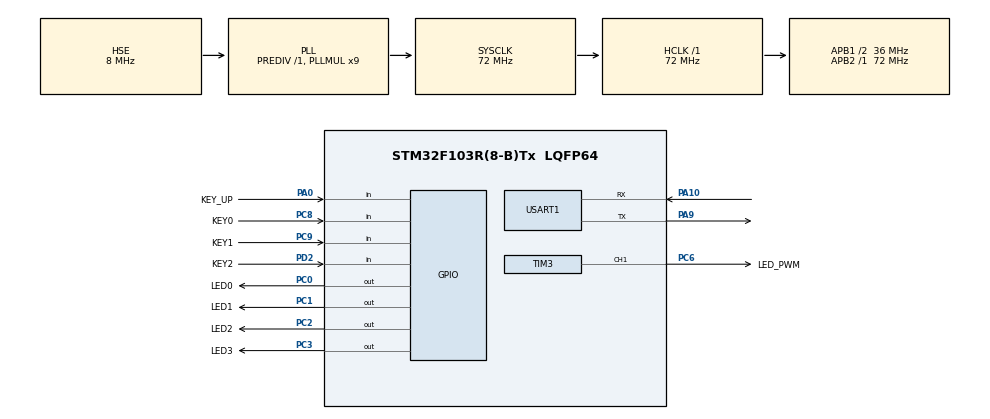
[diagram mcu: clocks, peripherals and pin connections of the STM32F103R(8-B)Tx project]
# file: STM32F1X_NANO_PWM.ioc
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Mcu.Family=STM32F1
Mcu.Name=STM32F103R(8-B)Tx
Mcu.Package=LQFP64
NVIC.PriorityGroup=NVIC_PRIORITYGROUP_2
NVIC.TIM3_IRQn=true\:1\:0\:true\:false\:true\:true\:true\:true
PA0-WKUP.GPIO_Label=KEY_UP
PA0-WKUP.GPIO_PuPd=GPIO_PULLDOWN
PA0-WKUP.Signal=GPIO_Input
PA10.Mode=Asynchronous
PA10.Signal=USART1_RX
PA9.Mode=Asynchronous
PA9.Signal=USART1_TX
PC0.GPIO_Label=LED0
PC0.Signal=GPIO_Output
PC1.GPIO_Label=LED1
PC1.Signal=GPIO_Output
PC14-OSC32_IN.Mode=LSE-External-Oscillator
PC14-OSC32_IN.Signal=RCC_OSC32_IN
PC15-OSC32_OUT.Mode=LSE-External-Oscillator
PC15-OSC32_OUT.Signal=RCC_OSC32_OUT
PC2.GPIO_Label=LED2
PC2.Signal=GPIO_Output
PC3.GPIO_Label=LED3
PC3.Signal=GPIO_Output
PC6.GPIO_Label=LED_PWM
PC6.Signal=S_TIM3_CH1
PC8.GPIO_Label=KEY0
PC8.GPIO_PuPd=GPIO_PULLUP
PC8.Signal=GPIO_Input
PC9.GPIO_Label=KEY1
PC9.GPIO_PuPd=GPIO_PULLUP
PC9.Signal=GPIO_Input
PD0-OSC_IN.Mode=HSE-External-Oscillator
PD0-OSC_IN.Signal=RCC_OSC_IN
PD1-OSC_OUT.Mode=HSE-External-Oscillator
PD1-OSC_OUT.Signal=RCC_OSC_OUT
PD2.GPIO_Label=KEY2
PD2.GPIO_PuPd=GPIO_PULLUP
PD2.Signal=GPIO_Input
ProjectManager.HeapSize=0x200
ProjectManager.StackSize=0x400
ProjectManager.TargetToolchain=STM32CubeIDE
RCC.AHBFreq_Value=72000000
RCC.APB1CLKDivider=RCC_HCLK_DIV2
RCC.APB1Freq_Value=36000000
RCC.APB1TimFreq_Value=72000000
RCC.APB2Freq_Value=72000000
RCC.APB2TimFreq_Value=72000000
RCC.HCLKFreq_Value=72000000
RCC.PLLMUL=RCC_PLL_MUL9
RCC.PLLSourceVirtual=RCC_PLLSOURCE_HSE
RCC.SYSCLKFreq_VALUE=72000000
RCC.SYSCLKSource=RCC_SYSCLKSOURCE_PLLCLK
RCC.USBFreq_Value=72000000
SH.S_TIM3_CH1.0=TIM3_CH1,PWM Generation1 CH1
TIM3.AutoReloadPreload=TIM_AUTORELOAD_PRELOAD_ENABLE
TIM3.Channel-PWM\ Generation1\ CH1=TIM_CHANNEL_1
TIM3.OCPolarity_1=TIM_OCPOLARITY_LOW
TIM3.Period=899
TIM3.Prescaler=0
TIM3.Pulse-PWM\ Generation1\ CH1=450
USART1.VirtualMode=VM_ASYNC
VP_SYS_VS_ND.Mode=No_Debug
VP_TIM3_VS_ClockSourceINT.Mode=Internal
board=custom

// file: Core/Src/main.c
/* USER CODE BEGIN Header */
/**
  ******************************************************************************
  * @file           : main.c
  * @brief          : Main program body
  ******************************************************************************
  * @attention
  *
  * Copyright (c) 2025 STMicroelectronics.
  * All rights reserved.
  *
  * This software is licensed under terms that can be found in the LICENSE file
  * in the root directory of this software component.
  * If no LICENSE file comes with this software, it is provided AS-IS.
  *
  ******************************************************************************
  */
/* USER CODE END Header */
#include "main.h"
#include "tim.h"
#include "usart.h"
#include "gpio.h"

/* USER CODE BEGIN Includes */
#include "common_inc.h"
#include "retarget.h"
/* USER CODE END Includes */

void SystemClock_Config(void);

int main(void)
{

  /* MCU Configuration--------------------------------------------------------*/

  /* Reset of all peripherals, Initializes the Flash interface and the Systick. */
  HAL_Init();

  /* Configure the system clock */
  SystemClock_Config();

  /* Initialize all configured peripherals */
  MX_GPIO_Init();
  MX_USART1_UART_Init();
  MX_TIM3_Init();
  /* USER CODE BEGIN 2 */
    RetargetInit(&huart1);
    bsp_init();
  /* USER CODE END 2 */

  /* Infinite loop */
  while (1)
  {

    /* USER CODE BEGIN 3 */
    user_main();
  }
  /* USER CODE END 3 */
}

void SystemClock_Config(void)
{
  RCC_OscInitTypeDef RCC_OscInitStruct = {0};
  RCC_ClkInitTypeDef RCC_ClkInitStruct = {0};

  /** Initializes the RCC Oscillators according to the specified parameters
  * in the RCC_OscInitTypeDef structure.
  */
  RCC_OscInitStruct.OscillatorType = RCC_OSCILLATORTYPE_HSE;
  RCC_OscInitStruct.HSEState = RCC_HSE_ON;
  RCC_OscInitStruct.HSEPredivValue = RCC_HSE_PREDIV_DIV1;
  RCC_OscInitStruct.HSIState = RCC_HSI_ON;
  RCC_OscInitStruct.PLL.PLLState = RCC_PLL_ON;
  RCC_OscInitStruct.PLL.PLLSource = RCC_PLLSOURCE_HSE;
  RCC_OscInitStruct.PLL.PLLMUL = RCC_PLL_MUL9;
  if (HAL_RCC_OscConfig(&RCC_OscInitStruct) != HAL_OK)
  {
    Error_Handler();
  }

  /** Initializes the CPU, AHB and APB buses clocks
  */
  RCC_ClkInitStruct.ClockType = RCC_CLOCKTYPE_HCLK|RCC_CLOCKTYPE_SYSCLK
                              |RCC_CLOCKTYPE_PCLK1|RCC_CLOCKTYPE_PCLK2;
  RCC_ClkInitStruct.SYSCLKSource = RCC_SYSCLKSOURCE_PLLCLK;
  RCC_ClkInitStruct.AHBCLKDivider = RCC_SYSCLK_DIV1;
  RCC_ClkInitStruct.APB1CLKDivider = RCC_HCLK_DIV2;
  RCC_ClkInitStruct.APB2CLKDivider = RCC_HCLK_DIV1;

  if (HAL_RCC_ClockConfig(&RCC_ClkInitStruct, FLASH_LATENCY_2) != HAL_OK)
  {
    Error_Handler();
  }
}

void Error_Handler(void)
{
  __disable_irq();
  while (1)
  {
  }
}
